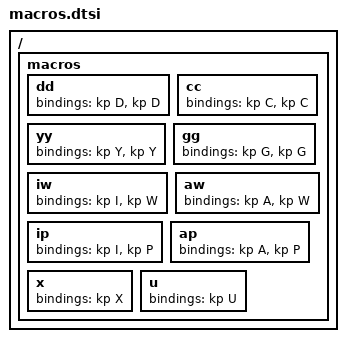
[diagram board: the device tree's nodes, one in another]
/ {
  macros {
    /* 行操作 */
    dd: dd { bindings = <&kp D &kp D>; };  /* 行削除 */
    cc: cc { bindings = <&kp C &kp C>; };  /* 行変更 */
    yy: yy { bindings = <&kp Y &kp Y>; };  /* 行ヤンク */

    /* ナビゲーション */
    gg: gg { bindings = <&kp G &kp G>; };  /* ファイル先頭 */

    /* テキストオブジェクト */
    iw: iw { bindings = <&kp I &kp W>; };  /* inside word */
    aw: aw { bindings = <&kp A &kp W>; };  /* around word */
    ip: ip { bindings = <&kp I &kp P>; };  /* inside paragraph */
    ap: ap { bindings = <&kp A &kp P>; };  /* around paragraph */

    /* その他編集 */
    x: x { bindings = <&kp X>; };          /* delete char */
    u: u { bindings = <&kp U>; };          /* undo */
  };
};

